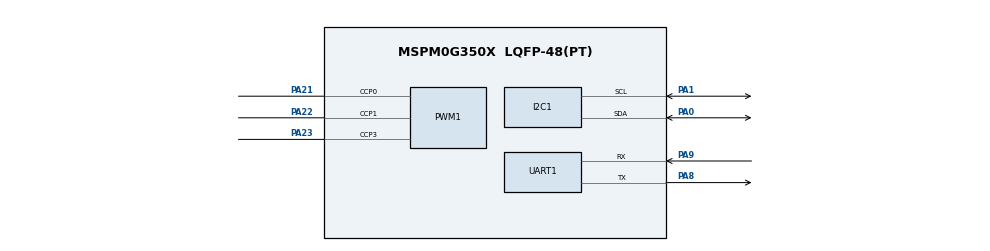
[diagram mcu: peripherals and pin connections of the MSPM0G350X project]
/**
 * Generated and validated for MSPM0 SDK 2.11.00.07 / SysConfig 1.28.
 * Open this file in SysConfig when changing pins or peripheral instances.
 *
 * @cliArgs --device "MSPM0G350X" --part "Default" --package "LQFP-48(PT)" --product "mspm0_sdk@2.11.00.07"
 * @versions {"tool":"1.28.0+4712"}
 */

const GPIO   = scripting.addModule("/ti/driverlib/GPIO", {}, false);
const GPIO1  = GPIO.addInstance();
const I2C    = scripting.addModule("/ti/driverlib/I2C", {}, false);
const I2C1   = I2C.addInstance();
const PWM    = scripting.addModule("/ti/driverlib/PWM", {}, false);
const PWM1   = PWM.addInstance();
const TIMER  = scripting.addModule("/ti/driverlib/TIMER", {}, false);
const TIMER1 = TIMER.addInstance();
const UART   = scripting.addModule("/ti/driverlib/UART", {}, false);
const UART1  = UART.addInstance();

GPIO1.$name                                 = "FOC_GPIO";
GPIO1.associatedPins.create(2);
GPIO1.associatedPins[0].$name               = "EN";
GPIO1.associatedPins[0].assignedPort        = "PORTA";
GPIO1.associatedPins[0].assignedPortSegment = "Upper";
GPIO1.associatedPins[0].assignedPin         = "24";
GPIO1.associatedPins[0].initialValue        = "CLEARED";
GPIO1.associatedPins[1].$name               = "NFAULT";
GPIO1.associatedPins[1].direction           = "INPUT";
GPIO1.associatedPins[1].assignedPort        = "PORTA";
GPIO1.associatedPins[1].assignedPortSegment = "Upper";
GPIO1.associatedPins[1].assignedPin         = "25";
GPIO1.associatedPins[1].internalResistor    = "PULL_UP";

I2C1.$name                             = "AS5600_I2C";
I2C1.basicEnableController             = true;
I2C1.basicControllerStandardBusSpeed   = "Fast";
I2C1.peripheral.$assign                = "I2C0";
I2C1.peripheral.sdaPin.$assign         = "PA0";
I2C1.peripheral.sclPin.$assign         = "PA1";
I2C1.sdaPinConfig.$name                = "ti_driverlib_gpio_GPIOPinGeneric0";
I2C1.sdaPinConfig.hideOutputInversion  = scripting.forceWrite(false);
I2C1.sdaPinConfig.onlyInternalResistor = scripting.forceWrite(false);
I2C1.sdaPinConfig.passedPeripheralType = scripting.forceWrite("Digital");
I2C1.sclPinConfig.$name                = "ti_driverlib_gpio_GPIOPinGeneric1";
I2C1.sclPinConfig.hideOutputInversion  = scripting.forceWrite(false);
I2C1.sclPinConfig.onlyInternalResistor = scripting.forceWrite(false);
I2C1.sclPinConfig.passedPeripheralType = scripting.forceWrite("Digital");

PWM1.$name                              = "FOC_PWM";
PWM1.clockSource                        = "BUSCLK";
PWM1.clockDivider                       = 1;
PWM1.clockPrescale                      = 1;
PWM1.timerCount                         = 1600;
PWM1.timerStartTimer                    = false;
PWM1.pwmMode                            = "CENTER_ALIGN";
PWM1.ccIndex                            = [0,1,3];
PWM1.peripheral.$assign                 = "TIMA0";
PWM1.peripheral.ccp0Pin.$assign         = "PA21";
PWM1.peripheral.ccp1Pin.$assign         = "PA22";
PWM1.peripheral.ccp3Pin.$assign         = "PA23";
PWM1.PWM_CHANNEL_0.$name                = "ti_driverlib_pwm_PWMTimerCC0";
PWM1.PWM_CHANNEL_0.dutyCycle            = 50;
PWM1.PWM_CHANNEL_0.shadowUpdateMode     = "ZERO_EVT";
PWM1.PWM_CHANNEL_1.$name                = "ti_driverlib_pwm_PWMTimerCC1";
PWM1.PWM_CHANNEL_1.dutyCycle            = 50;
PWM1.PWM_CHANNEL_1.shadowUpdateMode     = "ZERO_EVT";
PWM1.PWM_CHANNEL_3.$name                = "ti_driverlib_pwm_PWMTimerCC3";
PWM1.PWM_CHANNEL_3.dutyCycle            = 50;
PWM1.PWM_CHANNEL_3.shadowUpdateMode     = "ZERO_EVT";
PWM1.ccp0PinConfig.$name                = "ti_driverlib_gpio_GPIOPinGeneric2";
PWM1.ccp1PinConfig.$name                = "ti_driverlib_gpio_GPIOPinGeneric3";
PWM1.ccp3PinConfig.$name                = "ti_driverlib_gpio_GPIOPinGeneric4";

TIMER1.$name              = "CONTROL_TICK";
TIMER1.timerMode          = "PERIODIC";
TIMER1.timerPeriod        = "1 ms";
TIMER1.timerClkPrescale   = 32;
TIMER1.interrupts         = ["ZERO"];
TIMER1.peripheral.$assign = "TIMG0";

UART1.$name                            = "CMD_UART";
UART1.targetBaudRate                   = 115200;
UART1.enabledInterrupts                = ["RX"];
UART1.peripheral.$assign               = "UART1";
UART1.peripheral.rxPin.$assign         = "PA9";
UART1.peripheral.txPin.$assign         = "PA8";
UART1.txPinConfig.$name                = "ti_driverlib_gpio_GPIOPinGeneric5";
UART1.txPinConfig.direction            = scripting.forceWrite("OUTPUT");
UART1.txPinConfig.hideOutputInversion  = scripting.forceWrite(false);
UART1.txPinConfig.onlyInternalResistor = scripting.forceWrite(false);
UART1.txPinConfig.passedPeripheralType = scripting.forceWrite("Digital");
UART1.rxPinConfig.$name                = "ti_driverlib_gpio_GPIOPinGeneric6";
UART1.rxPinConfig.hideOutputInversion  = scripting.forceWrite(false);
UART1.rxPinConfig.onlyInternalResistor = scripting.forceWrite(false);
UART1.rxPinConfig.passedPeripheralType = scripting.forceWrite("Digital");

const Board  = scripting.addModule("/ti/driverlib/Board", {}, false);
const SYSCTL = scripting.addModule("/ti/driverlib/SYSCTL", {}, false);

Board.peripheral.$suggestSolution             = "DEBUGSS";
Board.peripheral.swclkPin.$suggestSolution    = "PA20";
Board.peripheral.swdioPin.$suggestSolution    = "PA19";
SYSCTL.peripheral.$suggestSolution            = "SYSCTL";
GPIO1.associatedPins[0].pin.$suggestSolution  = "PA24";
GPIO1.associatedPins[1].pin.$suggestSolution  = "PA25";
